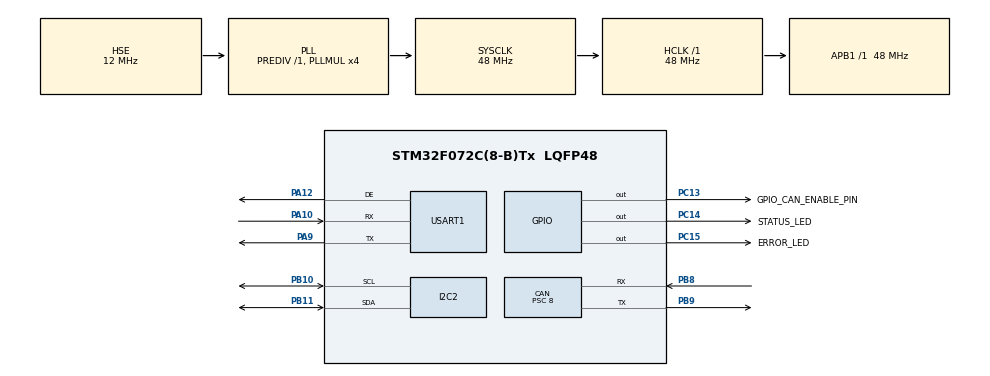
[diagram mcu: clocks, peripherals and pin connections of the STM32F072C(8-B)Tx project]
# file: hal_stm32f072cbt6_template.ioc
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CAN.ABOM=DISABLE
CAN.AWUM=DISABLE
CAN.BS1=CAN_BS1_16TQ
CAN.BS2=CAN_BS2_7TQ
CAN.CalculateBaudRate=250000
CAN.CalculateTimeBit=4000
CAN.CalculateTimeQuantum=166.66666666666666
CAN.NART=DISABLE
CAN.Prescaler=8
CAN.RFLM=DISABLE
CAN.SJW=CAN_SJW_4TQ
CAN.TTCM=DISABLE
CAN.TXFP=DISABLE
I2C2.Timing=0x20303E5D
IWDG.Prescaler=IWDG_PRESCALER_64
IWDG.Reload=3124
Mcu.Family=STM32F0
Mcu.Name=STM32F072C(8-B)Tx
Mcu.Package=LQFP48
PA10.Mode=Asynchronous
PA10.Signal=USART1_RX
PA12.Mode=Hardware Flow Control (RS485)
PA12.Signal=USART1_DE
PA13.Mode=Serial_Wire
PA13.Signal=SYS_SWDIO
PA14.Mode=Serial_Wire
PA14.Signal=SYS_SWCLK
PA9.Mode=Asynchronous
PA9.Signal=USART1_TX
PB10.Mode=I2C
PB10.Signal=I2C2_SCL
PB11.Mode=I2C
PB11.Signal=I2C2_SDA
PB8.Mode=CAN_Activate
PB8.Signal=CAN_RX
PB9.Mode=CAN_Activate
PB9.Signal=CAN_TX
PC13.GPIO_Label=GPIO_CAN_ENABLE_PIN
PC13.PinState=GPIO_PIN_SET
PC13.Signal=GPIO_Output
PC14-OSC32_IN.GPIO_Label=STATUS_LED
PC14-OSC32_IN.Signal=GPIO_Output
PC15-OSC32_OUT.GPIO_Label=ERROR_LED
PC15-OSC32_OUT.Signal=GPIO_Output
PF0-OSC_IN.Mode=HSE-External-Oscillator
PF0-OSC_IN.Signal=RCC_OSC_IN
PF1-OSC_OUT.Mode=HSE-External-Oscillator
PF1-OSC_OUT.Signal=RCC_OSC_OUT
ProjectManager.HeapSize=0x200
ProjectManager.StackSize=0x400
ProjectManager.TargetToolchain=STM32CubeIDE
RCC.AHBFreq_Value=48000000
RCC.APB1Freq_Value=48000000
RCC.APB1TimFreq_Value=48000000
RCC.HCLKFreq_Value=48000000
RCC.HSE_VALUE=12000000
RCC.PLLMUL=RCC_PLL_MUL4
RCC.PLLSourceVirtual=RCC_PLLSOURCE_HSE
RCC.SYSCLKFreq_VALUE=48000000
RCC.SYSCLKSource=RCC_SYSCLKSOURCE_PLLCLK
USART1.VirtualMode-Asynchronous=VM_ASYNC
USART1.VirtualMode-Hardware\ Flow\ Control\ (RS485)=VM_ASYNC
VP_IWDG_VS_IWDG.Mode=IWDG_Activate
board=custom

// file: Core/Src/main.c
/* USER CODE BEGIN Header */
/**
  ******************************************************************************
  * @file           : main.c
  * @brief          : Main program body
  ******************************************************************************
  * @attention
  *
  * Copyright (c) 2023 STMicroelectronics.
  * All rights reserved.
  *
  * This software is licensed under terms that can be found in the LICENSE file
  * in the root directory of this software component.
  * If no LICENSE file comes with this software, it is provided AS-IS.
  *
  ******************************************************************************
  */
/* USER CODE END Header */
#include "main.h"
#include "can.h"
#include "i2c.h"
#include "iwdg.h"
#include "usart.h"
#include "gpio.h"

/* USER CODE BEGIN Includes */
#include "app_task.h"

/* USER CODE END Includes */

void SystemClock_Config(void);

int main(void)
{

  /* MCU Configuration--------------------------------------------------------*/

  /* Reset of all peripherals, Initializes the Flash interface and the Systick. */
  HAL_Init();

  /* Configure the system clock */
  SystemClock_Config();

  /* Initialize all configured peripherals */
  MX_GPIO_Init();
  MX_CAN_Init();
  MX_I2C2_Init();
 // MX_IWDG_Init();
  MX_USART1_UART_Init();

  /* Infinite loop */
  /* USER CODE BEGIN WHILE */
  while (1)
  {
	  app_task();
	  // Refresh the Watchdog timer
//	  HAL_IWDG_Refresh(&hiwdg);

    /* USER CODE END WHILE */

  }
}

void SystemClock_Config(void)
{
  RCC_OscInitTypeDef RCC_OscInitStruct = {0};
  RCC_ClkInitTypeDef RCC_ClkInitStruct = {0};
  RCC_PeriphCLKInitTypeDef PeriphClkInit = {0};

  /** Initializes the RCC Oscillators according to the specified parameters
  * in the RCC_OscInitTypeDef structure.
  */
  RCC_OscInitStruct.OscillatorType = RCC_OSCILLATORTYPE_LSI|RCC_OSCILLATORTYPE_HSE;
  RCC_OscInitStruct.HSEState = RCC_HSE_ON;
  RCC_OscInitStruct.LSIState = RCC_LSI_ON;
  RCC_OscInitStruct.PLL.PLLState = RCC_PLL_ON;
  RCC_OscInitStruct.PLL.PLLSource = RCC_PLLSOURCE_HSE;
  RCC_OscInitStruct.PLL.PLLMUL = RCC_PLL_MUL4;
  RCC_OscInitStruct.PLL.PREDIV = RCC_PREDIV_DIV1;
  if (HAL_RCC_OscConfig(&RCC_OscInitStruct) != HAL_OK)
  {
    Error_Handler();
  }

  /** Initializes the CPU, AHB and APB buses clocks
  */
  RCC_ClkInitStruct.ClockType = RCC_CLOCKTYPE_HCLK|RCC_CLOCKTYPE_SYSCLK
                              |RCC_CLOCKTYPE_PCLK1;
  RCC_ClkInitStruct.SYSCLKSource = RCC_SYSCLKSOURCE_PLLCLK;
  RCC_ClkInitStruct.AHBCLKDivider = RCC_SYSCLK_DIV1;
  RCC_ClkInitStruct.APB1CLKDivider = RCC_HCLK_DIV1;

  if (HAL_RCC_ClockConfig(&RCC_ClkInitStruct, FLASH_LATENCY_1) != HAL_OK)
  {
    Error_Handler();
  }
  PeriphClkInit.PeriphClockSelection = RCC_PERIPHCLK_USART1;
  PeriphClkInit.Usart1ClockSelection = RCC_USART1CLKSOURCE_PCLK1;
  if (HAL_RCCEx_PeriphCLKConfig(&PeriphClkInit) != HAL_OK)
  {
    Error_Handler();
  }
}

void Error_Handler(void)
{
  __disable_irq();
  while (1)
  {
  }
}
